AUTOSAR XML (schema 4-0-3)
package /ComponentTypes
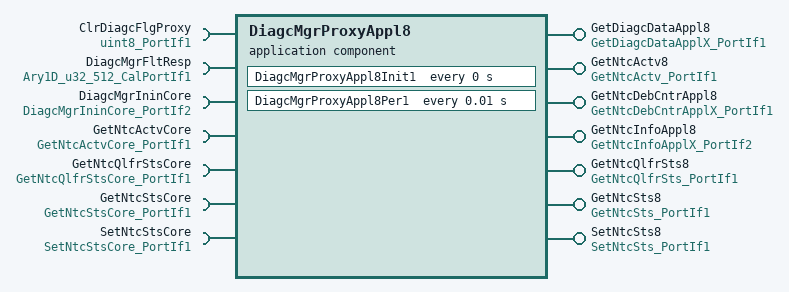
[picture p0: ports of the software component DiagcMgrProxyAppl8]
  application sw component type DiagcMgrProxyAppl8
    7 x provide port, all with server-com-spec{operation=Oper, queue-length=1}:
      GetDiagcDataAppl8: provided-interface=GetDiagcDataApplX_PortIf1
      GetNtcActv8: provided-interface=GetNtcActv_PortIf1
      GetNtcDebCntrAppl8: provided-interface=GetNtcDebCntrApplX_PortIf1
      GetNtcInfoAppl8: provided-interface=GetNtcInfoApplX_PortIf2
      GetNtcQlfrSts8: provided-interface=GetNtcQlfrSts_PortIf1
      GetNtcSts8: provided-interface=GetNtcSts_PortIf1
      SetNtcSts8: provided-interface=SetNtcSts_PortIf1
    7 x require port:
      ClrDiagcFlgProxy: nonqueued-receiver-com-spec{data-element=Val, filter=data-filter-type=ALWAYS, init-value=0}, required-interface=uint8_PortIf1
      DiagcMgrFltResp: parameter-require-com-spec{init-value=[0, 2147487488, 2147487488, 2147487488, 2147487488, 2147487488, 2147487488, 2147487488, 2147487488, 2147487488, 2147487488, 2147487488, 2147487488, 2147487488, 2147487488, 2147487488, 2147487488, 2147487488, 2147487488, 2147487488, 2147487488, 2147487488, 2147487488, 2147487488, 2147487488, 2147487488, 2147487488, 2147487488, 2147487488, 2147487488, 2147487488, 2147487488, 2147487488, 2147487488, 2147487488, 2147487488, 2147487488, 2147487488, 2147487488, 2147487488, 2147487488, 2147487488, 2147487488, 2147487488, 2147487488, 2147487488, 2147487488, 2147487488, 2147487488, 2147487488, 2147487488, 2147487488, 2147487488, 2147487488, 2147487488, 2147487488, 2147487488, 2147487488, 2147487488, 2147487488, 2147487488, 2147487488, 2147487488, 2147487488, 2147487488, 2147487488, 2147487488, 2147487488, 2147487488, 2147487488, 2147487488, 2147487488, 2147487488, 2147487488, 2147487488, 2147487488, 2147487488, 2147487488, 2147487488, 2147487488, 2147487488, 2147487488, 2147487488, 2147487488, 2147487488, 2147487488, 2147487488, 2147487488, 2147487488, 2147487488, 2147487488, 2147487488, 2147487488, 2147487488, 2147487488, 2147487488, 2147487488, 2147487488, 2147487488, 2147487488, 2147487488, 2147487488, 2147487488, 2147487488, 2147487488, 2147487488, 2147487488, 2147487488, 2147487488, 2147487488, 2147487488, 2147487488, 2147487488, 2147487488, 2147487488, 2147487488, 2147487488, 2147487488, 2147487488, 2147487488, 2147487488, 2147487488, 2147487488, 2147487488, 2147487488, 2147487488, 2147487488, 2147487488, 2147487488, 2147487488, 2147487488, 2147487488, 2147487488, 2147487488, 2147487488, 2147487488, 2147487488, 2147487488, 2147487488, 2147487488, 2147487488, 2147487488, 2147487488, 2147487488, 2147487488, 2147487488, 2147487488, 2147487488, 2147487488, 2147487488, 2147487488, 2147487488, 2147487488, 2147487488, 2147487488, 2147487488, 2147487488, 2147487488, 2147487488, 2147487488, 2147487488, 2147487488, 2147487488, 2147487488, 2147487488, 2147487488, 2147487488, 2147487488, 2147487488, 2147487488, 2147487488, 2147487488, 2147487488, 2147487488, 2147487488, 2147487488, 2147487488, 2147487488, 2147487488, 2147487488, 2147487488, 2147487488, 2147487488, 2147487488, 2147487488, 2147487488, 2147487488, 2147487488, 2147487488, 2147487488, 2147487488, 2147487488, 2147487488, 2147487488, 2147487488, 2147487488, 2147487488, 2147487488, 2147487488, 2147487488, 2147487488, 2147487488, 2147487488, 2147487488, 2147487488, 2147487488, 2147487488, 2147487488, 2147487488, 2147487488, 2147487488, 2147487488, 2147487488, 2147487488, 2147487488, 2147487488, 2147487488, 2147487488, 2147487488, 2147487488, 2147487488, 2147487488, 2147487488, 2147487488, 2147487488, 2147487488, 2147487488, 2147487488, 2147487488, 2147487488, 2147487488, 2147487488, 2147487488, 2147487488, 2147487488, 2147487488, 2147487488, 2147487488, 2147487488, 2147487488, 2147487488, 2147487488, 2147487488, 2147487488, 2147487488, 2147487488, 2147487488, 2147487488, 2147487488, 2147487488, 2147487488, 2147487488, 2147487488, 2147487488, 2147487488, 2147487488, 2147487488, 2147487488, 2147487488, 2147487488, 2147487488, 2147487488, 2147487488, 2147487488, 2147487488, 2147487488, 2147487488, 2147487488, 2147487488, 2147487488, 2147487488, 2147487488, 2147487488, 2147487488, 2147487488, 2147487488, 2147487488, 2147487488, 2147487488, 2147487488, 2147487488, 2147487488, 2147487488, 2147487488, 2147487488, 2147487488, 2147487488, 2147487488, 2147487488, 2147487488, 2147487488, 2147487488, 2147487488, 2147487488, 2147487488, 2147487488, 2147487488, 2147487488, 2147487488, 2147487488, 2147487488, 2147487488, 2147487488, 2147487488, 2147487488, 2147487488, 2147487488, 2147487488, 2147487488, 2147487488, 2147487488, 2147487488, 2147487488, 2147487488, 2147487488, 2147487488, 2147487488, 2147487488, 2147487488, 2147487488, 2147487488, 2147487488, 2147487488, 2147487488, 2147487488, 2147487488, 2147487488, 2147487488, 2147487488, 2147487488, 2147487488, 2147487488, 2147487488, 2147487488, 2147487488, 2147487488, 2147487488, 2147487488, 2147487488, 2147487488, 2147487488, 2147487488, 2147487488, 2147487488, 2147487488, 2147487488, 2147487488, 2147487488, 2147487488, 2147487488, 2147487488, 2147487488, 2147487488, 2147487488, 2147487488, 2147487488, 2147487488, 2147487488, 2147487488, 2147487488, 2147487488, 2147487488, 2147487488, 2147487488, 2147487488, 2147487488, 2147487488, 2147487488, 2147487488, 2147487488, 2147487488, 2147487488, 2147487488, 2147487488, 2147487488, 2147487488, 2147487488, 2147487488, 2147487488, 2147487488, 2147487488, 2147487488, 2147487488, 2147487488, 2147487488, 2147487488, 2147487488, 2147487488, 2147487488, 2147487488, 2147487488, 2147487488, 2147487488, 2147487488, 2147487488, 2147487488, 2147487488, 2147487488, 2147487488, 2147487488, 2147487488, 2147487488, 2147487488, 2147487488, 2147487488, 2147487488, 2147487488, 2147487488, 2147487488, 2147487488, 2147487488, 2147487488, 2147487488, 2147487488, 2147487488, 2147487488, 2147487488, 2147487488, 2147487488, 2147487488, 2147487488, 2147487488, 2147487488, 2147487488, 2147487488, 2147487488, 2147487488, 2147487488, 2147487488, 2147487488, 2147487488, 2147487488, 2147487488, 2147487488, 2147487488, 2147487488, 2147487488, 2147487488, 2147487488, 2147487488, 2147487488, 2147487488, 2147487488, 2147487488, 2147487488, 2147487488, 2147487488, 2147487488, 2147487488, 2147487488, 2147487488, 2147487488, 2147487488, 2147487488, 2147487488, 2147487488, 2147487488, 2147487488, 2147487488, 2147487488, 2147487488, 2147487488, 2147487488, 2147487488, 2147487488, 2147487488, 2147487488, 2147487488, 2147487488, 2147487488, 2147487488, 2147487488, 2147487488, 2147487488, 2147487488, 2147487488, 2147487488, 2147487488, 2147487488, 2147487488, 2147487488, 2147487488, 2147487488, 2147487488, 2147487488, 2147487488, 2147487488, 2147487488, 2147487488, 2147487488, 2147487488, 2147487488, 2147487488, 2147487488, 2147487488, 2147487488, 2147487488, 2147487488, 2147487488, 2147487488, 2147487488, 2147487488, 2147487488, 2147487488, 2147487488, 2147487488, 2147487488, 2147487488, 2147487488, 2147487488, 2147487488, 2147487488], parameter=Ary1D}, required-interface=Ary1D_u32_512_CalPortIf1
      DiagcMgrIninCore: required-interface=DiagcMgrIninCore_PortIf2
      GetNtcActvCore: required-interface=GetNtcActvCore_PortIf1
      GetNtcQlfrStsCore: required-interface=GetNtcQlfrStsCore_PortIf1
      GetNtcStsCore: required-interface=GetNtcStsCore_PortIf1
      SetNtcStsCore: required-interface=SetNtcStsCore_PortIf1
    behavior DiagcMgrProxyAppl8_InternalBehavior
      exclusive area DiagcMgrProxyAppl8
      ar-typed-per-instance-memorys:
        5 x data:
          DiagcData8: sw-calibration-access=READ-ONLY, type=DiagcDataRec1
          DiagcMgrNtcInfo8Ary: type=Ary1D_NtcInfoRec4_DiagcMgrProxyAppl8
          DiagcMgrNtcInfo8DebCntrAry: type=Ary1D_s16_DiagcMgrProxyAppl8
          PrevClrNtcFlg8: sw-calibration-access=READ-ONLY, type=uint8
          ProxySetNtcData8: sw-calibration-access=READ-ONLY, type=DiagcDataRec1
      timing event DiagcMgrProxyAppl8_InitEvent: start-on-event=DiagcMgrProxyAppl8Init1, period=0
      timing event TMT_DiagcMgrProxyAppl8Per1: start-on-event=DiagcMgrProxyAppl8Per1, period=0.01
      7 x operation invoked event:
        OIT_GetDiagcDataAppl8_Oper_GetDiagcDataAppl8_Oper: start-on-event=GetDiagcDataAppl8_Oper, operation=GetDiagcDataAppl8.Oper
        OIT_GetNtcActv8_Oper_GetNtcActv8_Oper: start-on-event=GetNtcActv8_Oper, operation=GetNtcActv8.Oper
        OIT_GetNtcDebCntrAppl8_Oper_GetNtcDebCntrAppl8_Oper: start-on-event=GetNtcDebCntrAppl8_Oper, operation=GetNtcDebCntrAppl8.Oper
        OIT_GetNtcInfoAppl8_Oper_GetNtcInfoAppl8_Oper: start-on-event=GetNtcInfoAppl8_Oper, operation=GetNtcInfoAppl8.Oper
        OIT_GetNtcQlfrSts8_Oper_GetNtcQlfrSts8_Oper: start-on-event=GetNtcQlfrSts8_Oper, operation=GetNtcQlfrSts8.Oper
        OIT_GetNtcSts8_Oper_GetNtcSts8_Oper: start-on-event=GetNtcSts8_Oper, operation=GetNtcSts8.Oper
        OIT_SetNtcSts8_Oper_SetNtcSts8_Oper: start-on-event=SetNtcSts8_Oper, operation=SetNtcSts8.Oper
      9 x runnable:
        DiagcMgrProxyAppl8Init1
          sync call SC_DiagcMgrIninCore_Oper: operation=DiagcMgrIninCore.Oper, timeout=0
        DiagcMgrProxyAppl8Per1: can-enter-exclusive-area=DiagcMgrProxyAppl8
          data-receive-point-by-arguments:
            access REC_ClrNtcFlg_Val: accessed-variable=ClrDiagcFlgProxy.Val
        GetDiagcDataAppl8_Oper
        GetNtcActv8_Oper: can-be-invoked-concurrently=true
          sync call SC_GetNtcActvCore_Oper: operation=GetNtcActvCore.Oper, timeout=0
        GetNtcDebCntrAppl8_Oper
        GetNtcInfoAppl8_Oper
        GetNtcQlfrSts8_Oper: can-be-invoked-concurrently=true
          sync call SC_GetNtcQlfrStsCore_Oper: operation=GetNtcQlfrStsCore.Oper, timeout=0
        GetNtcSts8_Oper: can-be-invoked-concurrently=true
          sync call SC_GetNtcStsCore_Oper: operation=GetNtcStsCore.Oper, timeout=0
        SetNtcSts8_Oper: can-be-invoked-concurrently=true
          sync call SC_SetNtcStsCore_Oper: operation=SetNtcStsCore.Oper, timeout=0
  swc implementation DiagcMgrProxyAppl8_Implementation: behavior=DiagcMgrProxyAppl8_InternalBehavior
    code-descriptors:
      code Default: artifact-descriptors=autosar-engineering-object={short-label=Default, category=SWSRC}
